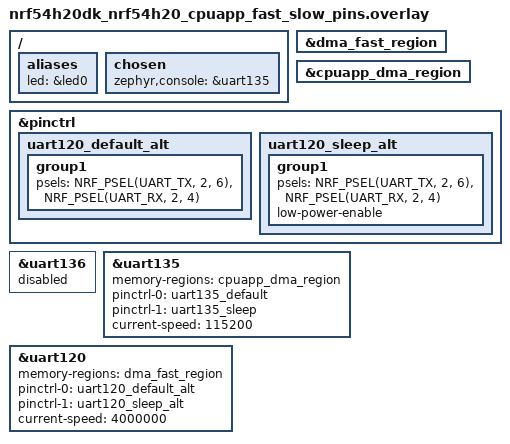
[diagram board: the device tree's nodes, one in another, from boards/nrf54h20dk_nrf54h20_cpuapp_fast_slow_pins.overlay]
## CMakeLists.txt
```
#
# Copyright (c) 2024 Nordic Semiconductor ASA
#
# SPDX-License-Identifier: LicenseRef-Nordic-5-Clause
#

cmake_minimum_required(VERSION 3.20.0)

find_package(Zephyr REQUIRED HINTS $ENV{ZEPHYR_BASE})

if(NOT SYSBUILD)
	message(FATAL_ERROR
		" This is a multi-image application that should be built using sysbuild.\n"
		" Add --sysbuild argument to west build command to prepare all the images.")
endif()

project(idle_uarte)

target_sources(app PRIVATE src/main.c)
```

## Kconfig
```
#
# Copyright (c) 2024 Nordic Semiconductor ASA
#
# SPDX-License-Identifier: LicenseRef-Nordic-5-Clause
#

choice GLOBAL_DOMAIN_CLOCK_FREQUENCY_OPTION
	prompt "Global domain clock frequency"
	default GLOBAL_DOMAIN_CLOCK_FREQUENCY_OPTION_320MHZ

config GLOBAL_DOMAIN_CLOCK_FREQUENCY_OPTION_320MHZ
	bool "320MHz"

config GLOBAL_DOMAIN_CLOCK_FREQUENCY_OPTION_256MHZ
	bool "256MHz"

config GLOBAL_DOMAIN_CLOCK_FREQUENCY_OPTION_128MHZ
	bool "128MHz"

config GLOBAL_DOMAIN_CLOCK_FREQUENCY_OPTION_64MHZ
	bool "64MHz"

endchoice

config GLOBAL_DOMAIN_CLOCK_FREQUENCY_MHZ
	int
	default 320 if GLOBAL_DOMAIN_CLOCK_FREQUENCY_OPTION_320MHZ
	default 256 if GLOBAL_DOMAIN_CLOCK_FREQUENCY_OPTION_256MHZ
	default 128 if GLOBAL_DOMAIN_CLOCK_FREQUENCY_OPTION_128MHZ
	default 64 if GLOBAL_DOMAIN_CLOCK_FREQUENCY_OPTION_64MHZ

config GLOBAL_DOMAIN_CLOCK_FREQUENCY_SWITCHING
	bool "Enable global domain frequency changing when driver is active"

source "Kconfig.zephyr"
```

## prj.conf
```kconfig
CONFIG_SERIAL=y
CONFIG_MAIN_STACK_SIZE=2048
CONFIG_UART_ASYNC_API=y
CONFIG_UART_USE_RUNTIME_CONFIGURE=y

CONFIG_PM=y
CONFIG_PM_S2RAM=y
CONFIG_PM_S2RAM_CUSTOM_MARKING=y
CONFIG_PM_DEVICE=y
CONFIG_PM_DEVICE_RUNTIME=y
CONFIG_POWEROFF=y

CONFIG_BOOT_BANNER=n
CONFIG_ASSERT=y

# Enable for debugging purposes only
CONFIG_PRINTK=n
CONFIG_LOG=n
CONFIG_CONSOLE=n
CONFIG_UART_CONSOLE=n
```

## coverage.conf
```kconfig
CONFIG_SERIAL=y
CONFIG_MAIN_STACK_SIZE=2048
CONFIG_UART_ASYNC_API=y
CONFIG_UART_USE_RUNTIME_CONFIGURE=y

CONFIG_PM=y
CONFIG_PM_S2RAM=n
CONFIG_PM_S2RAM_CUSTOM_MARKING=n
CONFIG_PM_DEVICE=y
CONFIG_PM_DEVICE_RUNTIME=y
CONFIG_POWEROFF=y

CONFIG_BOOT_BANNER=n
CONFIG_ASSERT=n
CONFIG_CLOCK_CONTROL=n

CONFIG_PRINTK=y
CONFIG_LOG=n
CONFIG_CONSOLE=y
CONFIG_UART_CONSOLE=y

CONFIG_LOG_BUFFER_SIZE=16384
```

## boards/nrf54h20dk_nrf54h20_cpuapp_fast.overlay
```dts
/*
 * Copyright (c) 2024 Nordic Semiconductor ASA
 *
 * SPDX-License-Identifier: LicenseRef-Nordic-5-Clause
 */

/ {
	aliases {
		led = &led0;
		/delete-property/ led1;
	};
};

/delete-node/ &led1;

&dma_fast_region {
	status = "okay";
};

/* UART device used for test
 * not the default UART assignment for the LD
 */
&pinctrl {
	uart120_default_alt: uart120_default_alt {
		group1 {
			psels = <NRF_PSEL(UART_TX, 7, 7)>,
				<NRF_PSEL(UART_RX, 7, 4)>;
		};
	};

	uart120_sleep_alt: uart120_sleep_alt {
		group1 {
			psels = <NRF_PSEL(UART_TX, 7, 7)>,
				<NRF_PSEL(UART_RX, 7, 4)>;
			low-power-enable;
		};
	};
};

dut: &uart120 {
	status = "okay";
	memory-regions = <&dma_fast_region>;
	pinctrl-0 = <&uart120_default_alt>;
	pinctrl-1 = <&uart120_sleep_alt>;
	pinctrl-names = "default", "sleep";
	current-speed = <4000000>;
};
```

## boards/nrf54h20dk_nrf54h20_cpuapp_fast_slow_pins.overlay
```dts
/*
 * Copyright (c) 2024 Nordic Semiconductor ASA
 *
 * SPDX-License-Identifier: LicenseRef-Nordic-5-Clause
 */

/*
 * To execute this test case the following loopback
 * is required: P2.04 <--> P2.06
 * Note: Console UART is connected to P1 (if02)
 */

/ {
	aliases {
		led = &led0;
		/delete-property/ led1;
	};

	chosen {
		zephyr,console = &uart135;
	};
};

/delete-node/ &led1;

&dma_fast_region {
	status = "okay";
};

&cpuapp_dma_region {
	status = "okay";
};

&pinctrl {
	uart120_default_alt: uart120_default_alt {
		group1 {
			psels = <NRF_PSEL(UART_TX, 2, 6)>,
				<NRF_PSEL(UART_RX, 2, 4)>;
		};
	};

	uart120_sleep_alt: uart120_sleep_alt {
		group1 {
			psels = <NRF_PSEL(UART_TX, 2, 6)>,
				<NRF_PSEL(UART_RX, 2, 4)>;
			low-power-enable;
		};
	};
};

&uart136 {
	status = "disabled";
	/delete-property/ memory-regions;
};

&uart135 {
	status = "okay";
	memory-regions = <&cpuapp_dma_region>;
	pinctrl-0 = <&uart135_default>;
	pinctrl-1 = <&uart135_sleep>;
	pinctrl-names = "default", "sleep";
	current-speed = <115200>;
	/delete-property/ hw-flow-control;
};

dut: &uart120 {
	status = "okay";
	memory-regions = <&dma_fast_region>;
	pinctrl-0 = <&uart120_default_alt>;
	pinctrl-1 = <&uart120_sleep_alt>;
	pinctrl-names = "default", "sleep";
	current-speed = <4000000>;
	/delete-property/ hw-flow-control;
};
```

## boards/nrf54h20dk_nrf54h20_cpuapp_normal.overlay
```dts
/*
 * Copyright (c) 2024 Nordic Semiconductor ASA
 *
 * SPDX-License-Identifier: LicenseRef-Nordic-5-Clause
 */

/ {
	aliases {
		led = &led0;
		/delete-property/ led1;
	};
};

/delete-node/ &led1;

&cpuapp_dma_region {
	status="okay";
};

/* UART device used for test
 * not the default UART assignment for the LD
 */
&pinctrl {
	uart135_default_alt: uart135_default_alt {
		group1 {
			psels = <NRF_PSEL(UART_TX, 0, 6)>,
				<NRF_PSEL(UART_RX, 0, 7)>,
				<NRF_PSEL(UART_RTS, 0, 8)>,
				<NRF_PSEL(UART_CTS, 0, 9)>;
		};
	};

	uart135_sleep_alt: uart135_sleep_alt {
		group1 {
			psels = <NRF_PSEL(UART_TX, 0, 6)>,
				<NRF_PSEL(UART_RX, 0, 7)>,
				<NRF_PSEL(UART_RTS, 0, 8)>,
				<NRF_PSEL(UART_CTS, 0, 9)>;
			low-power-enable;
		};
	};
};

dut: &uart135 {
	status = "okay";
	memory-regions = <&cpuapp_dma_region>;
	pinctrl-0 = <&uart135_default_alt>;
	pinctrl-1 = <&uart135_sleep_alt>;
	pinctrl-names = "default", "sleep";
	current-speed = <115200>;
	hw-flow-control;
};
```

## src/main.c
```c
/*
 * Copyright (c) 2024 Nordic Semiconductor ASA
 *
 * SPDX-License-Identifier: LicenseRef-Nordic-5-Clause
 */

#include <zephyr/drivers/uart.h>
#include <zephyr/pm/device.h>
#include <zephyr/pm/device_runtime.h>
#include <zephyr/kernel.h>
#include <zephyr/logging/log.h>
#include <zephyr/devicetree/clocks.h>
#include <zephyr/drivers/clock_control/nrf_clock_control.h>
#include <zephyr/drivers/gpio.h>

/* Note: logging is normally disabled for this test
 * Enable only for debugging purposes
 */
LOG_MODULE_REGISTER(idle_uarte);

#if DT_NODE_EXISTS(DT_NODELABEL(dut))
#define UART_NODE DT_NODELABEL(dut)
#else
#error Improper device tree configuration, UARTE test node not available
#endif

#define TEST_BUFFER_LEN 512

static K_SEM_DEFINE(uart_rx_ready_sem, 0, 1);
static K_SEM_DEFINE(uart_tx_done_sem, 0, 1);

static const struct device *const uart_dev = DEVICE_DT_GET(UART_NODE);
static const struct device *const console_dev = DEVICE_DT_GET(DT_CHOSEN(zephyr_console));
static const struct gpio_dt_spec led = GPIO_DT_SPEC_GET(DT_ALIAS(led), gpios);

uint8_t test_pattern[TEST_BUFFER_LEN];
static uint8_t test_buffer[TEST_BUFFER_LEN];
static volatile uint8_t uart_error_counter;

#if defined(CONFIG_CLOCK_CONTROL)
const uint32_t freq[] = {320, 256, 128, 64};

/*
 * Set Global Domain frequency (HSFLL120)
 */
void set_global_domain_frequency(uint32_t freq)
{
	int err;
	int res;
	struct onoff_client cli;
	const struct device *hsfll_dev = DEVICE_DT_GET(DT_NODELABEL(hsfll120));
	const struct nrf_clock_spec clk_spec_global_hsfll = {.frequency = MHZ(freq)};

	printk("Requested frequency [Hz]: %d\n", clk_spec_global_hsfll.frequency);
	sys_notify_init_spinwait(&cli.notify);
	err = nrf_clock_control_request(hsfll_dev, &clk_spec_global_hsfll, &cli);
	__ASSERT((err >= 0 && err < 3), "Wrong nrf_clock_control_request return code");
	do {
		err = sys_notify_fetch_result(&cli.notify, &res);
		k_yield();
	} while (err == -EAGAIN);
	__ASSERT(err == 0, "Wrong clock control request return code");
	__ASSERT(res == 0, "Wrong clock control request response");
}
#endif /* CONFIG_CLOCK_CONTROL */

void timer_handler(struct k_timer *dummy)
{
	k_sem_give(&uart_tx_done_sem);
}

K_TIMER_DEFINE(timer, timer_handler, NULL);

/*
 * Callback function for UART async transmission
 */
static void async_uart_callback(const struct device *dev, struct uart_event *evt, void *user_data)
{
	printk("Callback !\n");
	switch (evt->type) {
	case UART_TX_DONE:
		printk("UART_TX_DONE\n");
		break;
	case UART_TX_ABORTED:
		printk("UART_TX_ABORTED\n");
		printk("Callback should not enter here\n");
		__ASSERT_NO_MSG(1 == 0);
		break;
	case UART_RX_RDY:
		printk("UART_RX_RDY\n");
		k_sem_give(&uart_rx_ready_sem);
		break;
	case UART_RX_BUF_RELEASED:
		printk("UART_RX_BUF_RELEASED\n");
		break;
	case UART_RX_BUF_REQUEST:
		printk("UART_RX_BUF_REQUEST\n");
		break;
	case UART_RX_DISABLED:
		printk("UART_RX_DISABLED\n");
		break;
	default:
		break;
	}
}

/* Helper function for enabling UART RX */
void enable_uart_rx(void)
{
	int err;
	do {
		err = uart_rx_enable(uart_dev, test_buffer, TEST_BUFFER_LEN, 1000);
	} while (err == -EBUSY);
	__ASSERT(err == 0, "Unexpected error when enabling UART RX: %d", err);
}

void set_test_pattern(void)
{
	for (uint32_t counter = 0; counter < TEST_BUFFER_LEN; counter++) {
		test_pattern[counter] = (uint8_t)(counter & 0xFF);
	}
}

int main(void)
{
	int err;
	uint8_t switch_flag;
	uint32_t counter;
	struct uart_config test_uart_config;

	err = gpio_is_ready_dt(&led);
	__ASSERT(err, "Error: GPIO Device not ready");

	err = gpio_pin_configure_dt(&led, GPIO_OUTPUT_ACTIVE);
	__ASSERT(err == 0, "Could not configure led GPIO");

#if defined(CONFIG_CLOCK_CONTROL)
	set_global_domain_frequency(CONFIG_GLOBAL_DOMAIN_CLOCK_FREQUENCY_MHZ);
#endif

	printk("Hello World! %s\n", CONFIG_BOARD_TARGET);
	printk("UART instance: %s\n", uart_dev->name);
	set_test_pattern();
	err = uart_config_get(uart_dev, &test_uart_config);
	__ASSERT(err == 0, "Failed to get uart config");
	gpio_pin_set_dt(&led, 0);
	k_msleep(10);
	gpio_pin_set_dt(&led, 1);

	err = uart_configure(uart_dev, &test_uart_config);
	__ASSERT(err == 0, "Unexpected error when configuring UART: %d", err);

	/* UART is disabled so expect error. */
	err = uart_rx_disable(uart_dev);
	__ASSERT(err == -EFAULT, "Expected an error when disabling RX");

	err = uart_callback_set(uart_dev, async_uart_callback, NULL);
	__ASSERT(err == 0, "Unexpected error when setting callback %d", err);

	if (IS_ENABLED(CONFIG_PM_DEVICE_RUNTIME)) {
		pm_device_runtime_enable(uart_dev);
		pm_device_runtime_enable(console_dev);
	}

	counter = 0;
	while (1) {
		switch_flag = 1;
		k_timer_start(&timer, K_SECONDS(1), K_NO_WAIT);
		while (k_sem_take(&uart_tx_done_sem, K_NO_WAIT) != 0) {
			enable_uart_rx();
			do {
				err = uart_tx(uart_dev, test_pattern, TEST_BUFFER_LEN, 1000000);
			} while (err == -EBUSY);
			__ASSERT(err == 0, "Unexpected error when sending UART TX data: %d", err);
#if defined(CONFIG_GLOBAL_DOMAIN_CLOCK_FREQUENCY_SWITCHING)
			if (switch_flag) {
				set_global_domain_frequency(freq[++counter % ARRAY_SIZE(freq)]);
				switch_flag = 0;
			}
#endif
			while (k_sem_take(&uart_rx_ready_sem, K_NO_WAIT) != 0) {
			};
			for (int index = 0; index < TEST_BUFFER_LEN; index++) {
				__ASSERT(test_buffer[index] == test_pattern[index],
					 "Recieived data byte %d does not match pattern 0x%x != "
					 "0x%x",
					 index, test_buffer[index], test_pattern[index]);
			}
		}
		gpio_pin_set_dt(&led, 0);
		k_msleep(1000);
		gpio_pin_set_dt(&led, 1);
#if defined(CONFIG_COVERAGE)
		if (switch_flag) {
			printk("Coverage analysis start\n");
			break;
		}
#endif
	}
	return 0;
}
```
